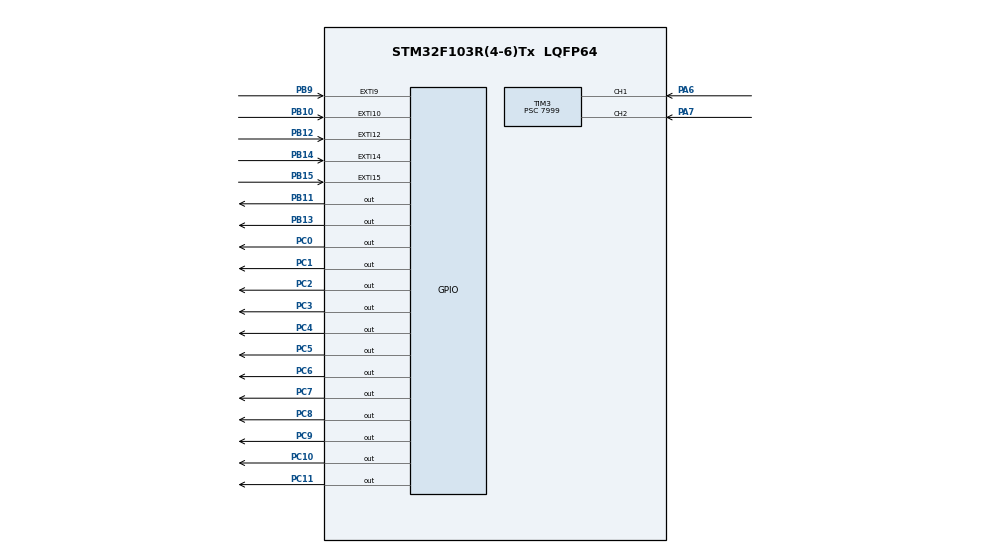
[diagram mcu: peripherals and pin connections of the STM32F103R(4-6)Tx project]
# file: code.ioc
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Mcu.Family=STM32F1
Mcu.Name=STM32F103R(4-6)Tx
Mcu.Package=LQFP64
NVIC.EXTI15_10_IRQn=true\:0\:0\:false\:false\:true\:true\:true
NVIC.EXTI9_5_IRQn=true\:0\:0\:false\:false\:true\:true\:true
NVIC.PriorityGroup=NVIC_PRIORITYGROUP_4
NVIC.TIM1_CC_IRQn=true\:0\:0\:false\:false\:true\:true\:true
NVIC.TIM1_UP_IRQn=true\:0\:0\:false\:false\:true\:true\:true
NVIC.TIM3_IRQn=true\:0\:0\:false\:false\:true\:true\:true
PA6.Signal=S_TIM3_CH1
PA7.Signal=S_TIM3_CH2
PB10.GPIO_ModeDefaultEXTI=GPIO_MODE_IT_RISING
PB10.Signal=GPXTI10
PB11.Signal=GPIO_Output
PB12.GPIO_ModeDefaultEXTI=GPIO_MODE_IT_FALLING
PB12.Signal=GPXTI12
PB13.Signal=GPIO_Output
PB14.Signal=GPXTI14
PB15.Signal=GPXTI15
PB9.Signal=GPXTI9
PC0.Signal=GPIO_Output
PC1.Signal=GPIO_Output
PC10.Signal=GPIO_Output
PC11.Signal=GPIO_Output
PC2.Signal=GPIO_Output
PC3.Signal=GPIO_Output
PC4.Signal=GPIO_Output
PC5.Signal=GPIO_Output
PC6.Signal=GPIO_Output
PC7.Signal=GPIO_Output
PC8.Signal=GPIO_Output
PC9.Signal=GPIO_Output
ProjectManager.HeapSize=0x200
ProjectManager.StackSize=0x400
ProjectManager.TargetToolchain=Makefile
RCC.APB1Freq_Value=8000000
RCC.APB2Freq_Value=8000000
SH.S_TIM3_CH1.0=TIM3_CH1,Input_Capture1_from_TI1
SH.S_TIM3_CH2.0=TIM3_CH2,Input_Capture2_from_TI2
TIM1.Period=79
TIM1.Prescaler=999
TIM3.Channel-Input_Capture1_from_TI1=TIM_CHANNEL_1
TIM3.Channel-Input_Capture2_from_TI2=TIM_CHANNEL_2
TIM3.ICPolarity_CH2=TIM_INPUTCHANNELPOLARITY_FALLING
TIM3.Period=9
TIM3.Prescaler=7999
VP_SYS_VS_ND.Mode=No_Debug
VP_TIM1_VS_ClockSourceINT.Mode=Internal
VP_TIM3_VS_ClockSourceINT.Mode=Internal
board=custom

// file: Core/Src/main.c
/* USER CODE BEGIN Header */
/**
  ******************************************************************************
  * @file           : main.c
  * @brief          : Main program body
  ******************************************************************************
  * @attention
  *
  * <h2><center>&copy; Copyright (c) 2022 STMicroelectronics.
  * All rights reserved.</center></h2>
  *
  * This software component is licensed by ST under BSD 3-Clause license,
  * the "License"; You may not use this file except in compliance with the
  * License. You may obtain a copy of the License at:
  *                        opensource.org/licenses/BSD-3-Clause
  *
  ******************************************************************************
  */
/* USER CODE END Header */
#include "main.h"
#include "tim.h"
#include "gpio.h"

/* USER CODE BEGIN Includes */
#include "display.h"
/* USER CODE END Includes */

void SystemClock_Config(void);

int main(void)
{

  /* MCU Configuration--------------------------------------------------------*/

  /* Reset of all peripherals, Initializes the Flash interface and the Systick. */
  HAL_Init();

  /* Configure the system clock */
  SystemClock_Config();

  /* Initialize all configured peripherals */
  MX_GPIO_Init();
  MX_TIM1_Init();
  MX_TIM3_Init();
  /* USER CODE BEGIN 2 */
  display();

  HAL_TIM_Base_Start_IT(&htim3);
  HAL_TIM_IC_Start_IT(&htim3, TIM_CHANNEL_1);
  HAL_TIM_IC_Start_IT(&htim3, TIM_CHANNEL_2);

  /* USER CODE END 2 */

  /* Infinite loop */
  while (1)
  {

  }
}

void SystemClock_Config(void)
{
  RCC_OscInitTypeDef RCC_OscInitStruct = {0};
  RCC_ClkInitTypeDef RCC_ClkInitStruct = {0};

  /** Initializes the RCC Oscillators according to the specified parameters
  * in the RCC_OscInitTypeDef structure.
  */
  RCC_OscInitStruct.OscillatorType = RCC_OSCILLATORTYPE_HSI;
  RCC_OscInitStruct.HSIState = RCC_HSI_ON;
  RCC_OscInitStruct.HSICalibrationValue = RCC_HSICALIBRATION_DEFAULT;
  RCC_OscInitStruct.PLL.PLLState = RCC_PLL_NONE;
  if (HAL_RCC_OscConfig(&RCC_OscInitStruct) != HAL_OK)
  {
    Error_Handler();
  }
  /** Initializes the CPU, AHB and APB buses clocks
  */
  RCC_ClkInitStruct.ClockType = RCC_CLOCKTYPE_HCLK|RCC_CLOCKTYPE_SYSCLK
                              |RCC_CLOCKTYPE_PCLK1|RCC_CLOCKTYPE_PCLK2;
  RCC_ClkInitStruct.SYSCLKSource = RCC_SYSCLKSOURCE_HSI;
  RCC_ClkInitStruct.AHBCLKDivider = RCC_SYSCLK_DIV1;
  RCC_ClkInitStruct.APB1CLKDivider = RCC_HCLK_DIV1;
  RCC_ClkInitStruct.APB2CLKDivider = RCC_HCLK_DIV1;

  if (HAL_RCC_ClockConfig(&RCC_ClkInitStruct, FLASH_LATENCY_0) != HAL_OK)
  {
    Error_Handler();
  }
}

void Error_Handler(void)
{
  __disable_irq();
  while (1)
  {
  }
}

/************************ (C) COPYRIGHT STMicroelectronics *****END OF FILE****/
